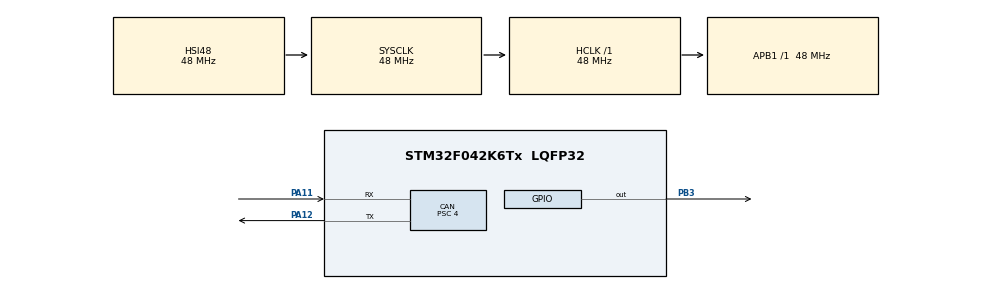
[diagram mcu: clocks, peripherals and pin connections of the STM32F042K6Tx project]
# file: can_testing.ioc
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CAN.BS1=CAN_BS1_7TQ
CAN.BS2=CAN_BS2_4TQ
CAN.CalculateTimeBit=1000
CAN.CalculateTimeQuantum=83.33333333333333
CAN.Prescaler=4
FREERTOS.Tasks01=defaultTask,0,128,StartDefaultTask,Default,NULL
Mcu.Family=STM32F0
Mcu.Name=STM32F042K6Tx
Mcu.Package=LQFP32
NVIC.CEC_CAN_IRQn=true\:3\:0\:false\:false\:true\:true
NVIC.TIM17_IRQn=true\:0\:0\:false\:false\:true\:false
NVIC.TimeBase=TIM17_IRQn
NVIC.TimeBaseIP=TIM17
PA11.Mode=Master
PA11.Signal=CAN_RX
PA12.Mode=Master
PA12.Signal=CAN_TX
PB3.Signal=GPIO_Output
ProjectManager.HeapSize=0x200
ProjectManager.StackSize=0x400
ProjectManager.TargetToolchain=Makefile
RCC.AHBFreq_Value=48000000
RCC.APB1Freq_Value=48000000
RCC.APB1TimFreq_Value=48000000
RCC.HCLKFreq_Value=48000000
RCC.SYSCLKFreq_VALUE=48000000
RCC.SYSCLKSource=RCC_SYSCLKSOURCE_HSI48
VP_FREERTOS_VS_ENABLE.Mode=Enabled
VP_SYS_VS_tim17.Mode=TIM17
board=can_testing

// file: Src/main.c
/**
  ******************************************************************************
  * File Name          : main.c
  * Description        : Main program body
  ******************************************************************************
  * This notice applies to any and all portions of this file
  * that are not between comment pairs USER CODE BEGIN and
  * USER CODE END. Other portions of this file, whether
  * inserted by the user or by software development tools
  * are owned by their respective copyright owners.
  *
  * Copyright (c) 2017 STMicroelectronics International N.V.
  * All rights reserved.
  *
  * Redistribution and use in source and binary forms, with or without
  * modification, are permitted, provided that the following conditions are met:
  *
  * 1. Redistribution of source code must retain the above copyright notice,
  *    this list of conditions and the following disclaimer.
  * 2. Redistributions in binary form must reproduce the above copyright notice,
  *    this list of conditions and the following disclaimer in the documentation
  *    and/or other materials provided with the distribution.
  * 3. Neither the name of STMicroelectronics nor the names of other
  *    contributors to this software may be used to endorse or promote products
  *    derived from this software without specific written permission.
  * 4. This software, including modifications and/or derivative works of this
  *    software, must execute solely and exclusively on microcontroller or
  *    microprocessor devices manufactured by or for STMicroelectronics.
  * 5. Redistribution and use of this software other than as permitted under
  *    this license is void and will automatically terminate your rights under
  *    this license.
  *
  * THIS SOFTWARE IS PROVIDED BY STMICROELECTRONICS AND CONTRIBUTORS "AS IS"
  * AND ANY EXPRESS, IMPLIED OR STATUTORY WARRANTIES, INCLUDING, BUT NOT
  * LIMITED TO, THE IMPLIED WARRANTIES OF MERCHANTABILITY, FITNESS FOR A
  * PARTICULAR PURPOSE AND NON-INFRINGEMENT OF THIRD PARTY INTELLECTUAL PROPERTY
  * RIGHTS ARE DISCLAIMED TO THE FULLEST EXTENT PERMITTED BY LAW. IN NO EVENT
  * SHALL STMICROELECTRONICS OR CONTRIBUTORS BE LIABLE FOR ANY DIRECT, INDIRECT,
  * INCIDENTAL, SPECIAL, EXEMPLARY, OR CONSEQUENTIAL DAMAGES (INCLUDING, BUT NOT
  * LIMITED TO, PROCUREMENT OF SUBSTITUTE GOODS OR SERVICES; LOSS OF USE, DATA,
  * OR PROFITS; OR BUSINESS INTERRUPTION) HOWEVER CAUSED AND ON ANY THEORY OF
  * LIABILITY, WHETHER IN CONTRACT, STRICT LIABILITY, OR TORT (INCLUDING
  * NEGLIGENCE OR OTHERWISE) ARISING IN ANY WAY OUT OF THE USE OF THIS SOFTWARE,
  * EVEN IF ADVISED OF THE POSSIBILITY OF SUCH DAMAGE.
  *
  ******************************************************************************
  */
#include "main.h"
#include "stm32f0xx_hal.h"
#include "cmsis_os.h"

CAN_HandleTypeDef hcan;

osThreadId defaultTaskHandle;

/* USER CODE BEGIN PV */
/* Private variables ---------------------------------------------------------*/
osThreadId canTaskHandle;
uint8_t count = 0;

/* USER CODE END PV */

void SystemClock_Config(void);
static void MX_GPIO_Init(void);
static void MX_CAN_Init(void);
void StartDefaultTask(void const * argument);

/* USER CODE BEGIN PFP */
/* Private function prototypes -----------------------------------------------*/
void StartCanTask(void const * argument);

/* USER CODE END PFP */

int main(void)
{

  /* MCU Configuration----------------------------------------------------------*/

  /* Reset of all peripherals, Initializes the Flash interface and the Systick. */
  HAL_Init();

  /* Configure the system clock */
  SystemClock_Config();

  /* Initialize all configured peripherals */
  MX_GPIO_Init();
  MX_CAN_Init();

  /* Create the thread(s) */
  /* definition and creation of defaultTask */
  osThreadDef(defaultTask, StartDefaultTask, osPriorityNormal, 0, 128);
  defaultTaskHandle = osThreadCreate(osThread(defaultTask), NULL);

  /* USER CODE BEGIN RTOS_THREADS */
  /* add threads, ... */
  osThreadDef(canTask, StartCanTask, osPriorityNormal, 0, 128);
  canTaskHandle = osThreadCreate(osThread(canTask), NULL);
  /* USER CODE END RTOS_THREADS */

  /* Start scheduler */
  osKernelStart();

  /* We should never get here as control is now taken by the scheduler */

  /* Infinite loop */
  while (1)
  {

  }

}

/** System Clock Configuration
*/
void SystemClock_Config(void)
{

  RCC_OscInitTypeDef RCC_OscInitStruct;
  RCC_ClkInitTypeDef RCC_ClkInitStruct;

    /**Initializes the CPU, AHB and APB busses clocks
    */
  RCC_OscInitStruct.OscillatorType = RCC_OSCILLATORTYPE_HSI48;
  RCC_OscInitStruct.HSI48State = RCC_HSI48_ON;
  RCC_OscInitStruct.PLL.PLLState = RCC_PLL_NONE;
  if (HAL_RCC_OscConfig(&RCC_OscInitStruct) != HAL_OK)
  {
    _Error_Handler(__FILE__, __LINE__);
  }

    /**Initializes the CPU, AHB and APB busses clocks
    */
  RCC_ClkInitStruct.ClockType = RCC_CLOCKTYPE_HCLK|RCC_CLOCKTYPE_SYSCLK
                              |RCC_CLOCKTYPE_PCLK1;
  RCC_ClkInitStruct.SYSCLKSource = RCC_SYSCLKSOURCE_HSI48;
  RCC_ClkInitStruct.AHBCLKDivider = RCC_SYSCLK_DIV1;
  RCC_ClkInitStruct.APB1CLKDivider = RCC_HCLK_DIV1;

  if (HAL_RCC_ClockConfig(&RCC_ClkInitStruct, FLASH_LATENCY_1) != HAL_OK)
  {
    _Error_Handler(__FILE__, __LINE__);
  }

    /**Configure the Systick interrupt time
    */
  HAL_SYSTICK_Config(HAL_RCC_GetHCLKFreq()/1000);

    /**Configure the Systick
    */
  HAL_SYSTICK_CLKSourceConfig(SYSTICK_CLKSOURCE_HCLK);

  /* SysTick_IRQn interrupt configuration */
  HAL_NVIC_SetPriority(SysTick_IRQn, 3, 0);
}

/* CAN init function */
static void MX_CAN_Init(void)
{

  hcan.Instance = CAN;
  hcan.Init.Prescaler = 4;
  hcan.Init.Mode = CAN_MODE_NORMAL;
  hcan.Init.SJW = CAN_SJW_1TQ;
  hcan.Init.BS1 = CAN_BS1_7TQ;
  hcan.Init.BS2 = CAN_BS2_4TQ;
  hcan.Init.TTCM = DISABLE;
  hcan.Init.ABOM = DISABLE;
  hcan.Init.AWUM = DISABLE;
  hcan.Init.NART = DISABLE;
  hcan.Init.RFLM = DISABLE;
  hcan.Init.TXFP = DISABLE;
  if (HAL_CAN_Init(&hcan) != HAL_OK)
  {
    _Error_Handler(__FILE__, __LINE__);
  }

}

/** Configure pins as
        * Analog
        * Input
        * Output
        * EVENT_OUT
        * EXTI
*/
static void MX_GPIO_Init(void)
{

  GPIO_InitTypeDef GPIO_InitStruct;

  /* GPIO Ports Clock Enable */
  __HAL_RCC_GPIOA_CLK_ENABLE();
  __HAL_RCC_GPIOB_CLK_ENABLE();

  /*Configure GPIO pin Output Level */
  HAL_GPIO_WritePin(GPIOB, GPIO_PIN_3, GPIO_PIN_RESET);

  /*Configure GPIO pin : PB3 */
  GPIO_InitStruct.Pin = GPIO_PIN_3;
  GPIO_InitStruct.Mode = GPIO_MODE_OUTPUT_PP;
  GPIO_InitStruct.Pull = GPIO_NOPULL;
  GPIO_InitStruct.Speed = GPIO_SPEED_FREQ_LOW;
  HAL_GPIO_Init(GPIOB, &GPIO_InitStruct);

}

/* USER CODE BEGIN 4 */

void StartCanTask(void const * argument)
{
  static CanTxMsgTypeDef TxMessage;
  static CanRxMsgTypeDef RxMessage;
  hcan.pTxMsg = &TxMessage;
  hcan.pRxMsg = &RxMessage;

  hcan.pTxMsg->ExtId = 0x1111;
  hcan.pTxMsg->IDE = CAN_ID_EXT;
  hcan.pTxMsg->RTR = CAN_RTR_DATA;
  hcan.pTxMsg->DLC = 8;

  CAN_FilterConfTypeDef  sFilterConfig;
  sFilterConfig.FilterNumber = 0;
  sFilterConfig.FilterMode = CAN_FILTERMODE_IDMASK;
  sFilterConfig.FilterScale = CAN_FILTERSCALE_32BIT;
  sFilterConfig.FilterIdHigh = 0x0000; // Set the filter to let everything through
  sFilterConfig.FilterIdLow = 0x0000;
  sFilterConfig.FilterMaskIdHigh = 0x0000;
  sFilterConfig.FilterMaskIdLow = 0x0000;
  sFilterConfig.FilterFIFOAssignment = 0;
  sFilterConfig.FilterActivation = ENABLE;
  sFilterConfig.BankNumber = 4; //Not entirely sure what this is for

  if (HAL_CAN_ConfigFilter(&hcan, &sFilterConfig) != HAL_OK)
  {
    /* Filter configuration Error */
    Error_Handler();
  }

  uint8_t receiveStatus = 0;
  receiveStatus = HAL_CAN_Receive_IT(&hcan, CAN_FIFO0);
  //__HAL_CAN_ENABLE_IT(&hcan, CAN_FIFO0);
  while(1)
  {
    //HAL_CAN_Receive(&hcan, CAN_FIFO0, 1000);
  //  count = hcan.pRxMsg->Data[0];
    //HAL_GPIO_TogglePin(GPIOB, GPIO_PIN_3);
    hcan.pTxMsg->Data[0] = count;
    hcan.pTxMsg->Data[1] = count;
    hcan.pTxMsg->Data[2] = count;
    hcan.pTxMsg->Data[3] = count;
    hcan.pTxMsg->Data[4] = count;
    hcan.pTxMsg->Data[5] = count;
    hcan.pTxMsg->Data[6] = receiveStatus;
    hcan.pTxMsg->Data[7] = 0;
    count++;
    HAL_CAN_Transmit_IT(&hcan);
    //hcan.pTxMsg->Data[7]++;
    //HAL_CAN_Transmit_IT(&hcan);
    //hcan.pTxMsg->Data[7]++;
    //HAL_CAN_Transmit_IT(&hcan);
    //HAL_CAN_Transmit(&hcan, 10);
    osDelay(200);
  }
}

void HAL_CAN_RxCpltCallback (CAN_HandleTypeDef * hcan)
{
  count = hcan->pRxMsg->Data[0];
  HAL_GPIO_TogglePin(GPIOB, GPIO_PIN_3);
  HAL_CAN_Receive_IT(hcan, CAN_FIFO0);
}

/* USER CODE END 4 */

/* StartDefaultTask function */
void StartDefaultTask(void const * argument)
{

  for(;;)
  {
    osDelay(1);
  }
}

void HAL_TIM_PeriodElapsedCallback(TIM_HandleTypeDef *htim)
{
  if (htim->Instance == TIM17) {
    HAL_IncTick();
  }
}

void _Error_Handler(char * file, int line)
{
  while(1)
  {
  }
}

/************************ (C) COPYRIGHT STMicroelectronics *****END OF FILE****/
